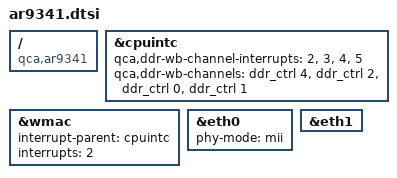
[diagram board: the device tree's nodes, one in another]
// SPDX-License-Identifier: GPL-2.0-or-later OR MIT

#include "ar934x.dtsi"

/ {
	compatible = "qca,ar9341";
};

&cpuintc {
	qca,ddr-wb-channel-interrupts = <2>, <3>, <4>, <5>;
	qca,ddr-wb-channels = <&ddr_ctrl 4>, <&ddr_ctrl 2>,
				<&ddr_ctrl 0>, <&ddr_ctrl 1>;
};

&wmac {
	interrupt-parent = <&cpuintc>;
	interrupts = <2>;
};

&eth0 {
	phy-mode = "mii";
};

&eth1 {
	status = "okay";
};
